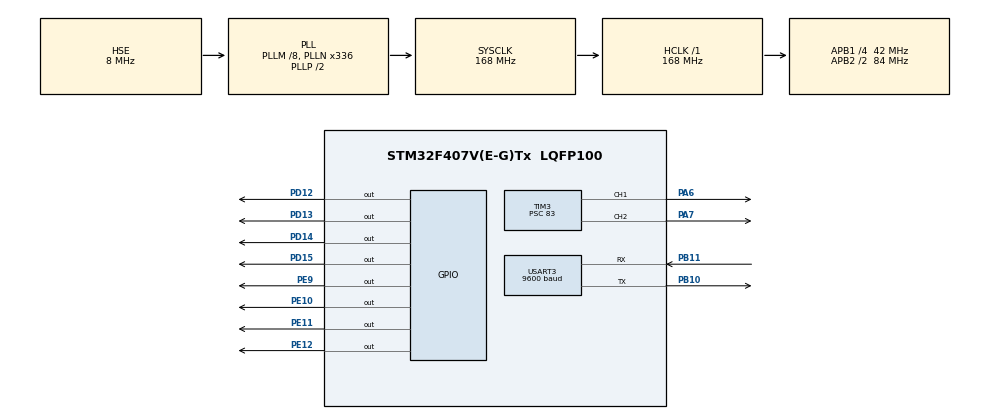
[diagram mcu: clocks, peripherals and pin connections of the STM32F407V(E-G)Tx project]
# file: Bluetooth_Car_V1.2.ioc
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Mcu.Family=STM32F4
Mcu.Name=STM32F407V(E-G)Tx
Mcu.Package=LQFP100
NVIC.PriorityGroup=NVIC_PRIORITYGROUP_0
NVIC.USART3_IRQn=true\:0\:0\:false\:false\:true\:true\:true
PA6.Signal=S_TIM3_CH1
PA7.Signal=S_TIM3_CH2
PB10.Mode=Asynchronous
PB10.Signal=USART3_TX
PB11.Mode=Asynchronous
PB11.Signal=USART3_RX
PD12.Signal=GPIO_Output
PD13.Signal=GPIO_Output
PD14.Signal=GPIO_Output
PD15.Signal=GPIO_Output
PE10.Signal=GPIO_Output
PE11.Signal=GPIO_Output
PE12.Signal=GPIO_Output
PE9.Signal=GPIO_Output
PH0-OSC_IN.Mode=HSE-External-Oscillator
PH0-OSC_IN.Signal=RCC_OSC_IN
PH1-OSC_OUT.Mode=HSE-External-Oscillator
PH1-OSC_OUT.Signal=RCC_OSC_OUT
ProjectManager.HeapSize=0x200
ProjectManager.StackSize=0x400
ProjectManager.TargetToolchain=STM32CubeIDE
RCC.48MHZClocksFreq_Value=48000000
RCC.AHBFreq_Value=168000000
RCC.APB1CLKDivider=RCC_HCLK_DIV4
RCC.APB1Freq_Value=42000000
RCC.APB1TimFreq_Value=84000000
RCC.APB2CLKDivider=RCC_HCLK_DIV2
RCC.APB2Freq_Value=84000000
RCC.APB2TimFreq_Value=168000000
RCC.CortexFreq_Value=168000000
RCC.HCLKFreq_Value=168000000
RCC.HSE_VALUE=8000000
RCC.HSI_VALUE=16000000
RCC.LSE_VALUE=32768
RCC.PLLM=8
RCC.PLLN=336
RCC.PLLQ=7
RCC.PLLSourceVirtual=RCC_PLLSOURCE_HSE
RCC.SYSCLKFreq_VALUE=168000000
RCC.SYSCLKSource=RCC_SYSCLKSOURCE_PLLCLK
RCC.VCOOutputFreq_Value=336000000
SH.S_TIM3_CH1.0=TIM3_CH1,PWM Generation1 CH1
SH.S_TIM3_CH2.0=TIM3_CH2,PWM Generation2 CH2
TIM3.Channel-PWM\ Generation1\ CH1=TIM_CHANNEL_1
TIM3.Channel-PWM\ Generation2\ CH2=TIM_CHANNEL_2
TIM3.Period=99
TIM3.Prescaler=83
USART3.BaudRate=9600
USART3.VirtualMode=VM_ASYNC
VP_TIM3_VS_ClockSourceINT.Mode=Internal
board=STM32F407G-DISC1

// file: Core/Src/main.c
/* USER CODE BEGIN Header */
/**
  ******************************************************************************
  * @file           : main.c
  * @brief          : Main program body
  ******************************************************************************
  * @attention
  *
  * <h2><center>&copy; Copyright (c) 2021 STMicroelectronics.
  * All rights reserved.</center></h2>
  *
  * This software component is licensed by ST under Ultimate Liberty license
  * SLA0044, the "License"; You may not use this file except in compliance with
  * the License. You may obtain a copy of the License at:
  *                             www.st.com/SLA0044
  *
  ******************************************************************************
  */
/* USER CODE END Header */
#include "main.h"

TIM_HandleTypeDef htim3;

UART_HandleTypeDef huart3;

void SystemClock_Config(void);
static void MX_GPIO_Init(void);
static void MX_USART3_UART_Init(void);
static void MX_TIM3_Init(void);

/* USER CODE BEGIN 0 */
extern char rx_buffer[50];
/* USER CODE END 0 */

int main(void)
{

  /* MCU Configuration--------------------------------------------------------*/

  /* Reset of all peripherals, Initializes the Flash interface and the Systick. */
  HAL_Init();

  /* Configure the system clock */
  SystemClock_Config();

  /* Initialize all configured peripherals */
  MX_GPIO_Init();
  MX_USART3_UART_Init();
  MX_TIM3_Init();
  /* USER CODE BEGIN 2 */

  HAL_UART_Receive_IT(&huart3, (uint8_t *)rx_buffer, 50);
  HAL_TIM_PWM_Start(&htim3, TIM_CHANNEL_1);
  HAL_TIM_PWM_Start(&htim3, TIM_CHANNEL_2);

  /* USER CODE END 2 */

  /* Infinite loop */
  while (1)
  {

  }
}

void SystemClock_Config(void)
{
  RCC_OscInitTypeDef RCC_OscInitStruct = {0};
  RCC_ClkInitTypeDef RCC_ClkInitStruct = {0};

  /** Configure the main internal regulator output voltage
  */
  __HAL_RCC_PWR_CLK_ENABLE();
  __HAL_PWR_VOLTAGESCALING_CONFIG(PWR_REGULATOR_VOLTAGE_SCALE1);
  /** Initializes the RCC Oscillators according to the specified parameters
  * in the RCC_OscInitTypeDef structure.
  */
  RCC_OscInitStruct.OscillatorType = RCC_OSCILLATORTYPE_HSE;
  RCC_OscInitStruct.HSEState = RCC_HSE_ON;
  RCC_OscInitStruct.PLL.PLLState = RCC_PLL_ON;
  RCC_OscInitStruct.PLL.PLLSource = RCC_PLLSOURCE_HSE;
  RCC_OscInitStruct.PLL.PLLM = 8;
  RCC_OscInitStruct.PLL.PLLN = 336;
  RCC_OscInitStruct.PLL.PLLP = RCC_PLLP_DIV2;
  RCC_OscInitStruct.PLL.PLLQ = 7;
  if (HAL_RCC_OscConfig(&RCC_OscInitStruct) != HAL_OK)
  {
    Error_Handler();
  }
  /** Initializes the CPU, AHB and APB buses clocks
  */
  RCC_ClkInitStruct.ClockType = RCC_CLOCKTYPE_HCLK|RCC_CLOCKTYPE_SYSCLK
                              |RCC_CLOCKTYPE_PCLK1|RCC_CLOCKTYPE_PCLK2;
  RCC_ClkInitStruct.SYSCLKSource = RCC_SYSCLKSOURCE_PLLCLK;
  RCC_ClkInitStruct.AHBCLKDivider = RCC_SYSCLK_DIV1;
  RCC_ClkInitStruct.APB1CLKDivider = RCC_HCLK_DIV4;
  RCC_ClkInitStruct.APB2CLKDivider = RCC_HCLK_DIV2;

  if (HAL_RCC_ClockConfig(&RCC_ClkInitStruct, FLASH_LATENCY_5) != HAL_OK)
  {
    Error_Handler();
  }
}

static void MX_TIM3_Init(void)
{

  TIM_ClockConfigTypeDef sClockSourceConfig = {0};
  TIM_MasterConfigTypeDef sMasterConfig = {0};
  TIM_OC_InitTypeDef sConfigOC = {0};

  htim3.Instance = TIM3;
  htim3.Init.Prescaler = 83;
  htim3.Init.CounterMode = TIM_COUNTERMODE_UP;
  htim3.Init.Period = 99;
  htim3.Init.ClockDivision = TIM_CLOCKDIVISION_DIV1;
  htim3.Init.AutoReloadPreload = TIM_AUTORELOAD_PRELOAD_DISABLE;
  if (HAL_TIM_Base_Init(&htim3) != HAL_OK)
  {
    Error_Handler();
  }
  sClockSourceConfig.ClockSource = TIM_CLOCKSOURCE_INTERNAL;
  if (HAL_TIM_ConfigClockSource(&htim3, &sClockSourceConfig) != HAL_OK)
  {
    Error_Handler();
  }
  if (HAL_TIM_PWM_Init(&htim3) != HAL_OK)
  {
    Error_Handler();
  }
  sMasterConfig.MasterOutputTrigger = TIM_TRGO_RESET;
  sMasterConfig.MasterSlaveMode = TIM_MASTERSLAVEMODE_DISABLE;
  if (HAL_TIMEx_MasterConfigSynchronization(&htim3, &sMasterConfig) != HAL_OK)
  {
    Error_Handler();
  }
  sConfigOC.OCMode = TIM_OCMODE_PWM1;
  sConfigOC.Pulse = 0;
  sConfigOC.OCPolarity = TIM_OCPOLARITY_HIGH;
  sConfigOC.OCFastMode = TIM_OCFAST_DISABLE;
  if (HAL_TIM_PWM_ConfigChannel(&htim3, &sConfigOC, TIM_CHANNEL_1) != HAL_OK)
  {
    Error_Handler();
  }
  if (HAL_TIM_PWM_ConfigChannel(&htim3, &sConfigOC, TIM_CHANNEL_2) != HAL_OK)
  {
    Error_Handler();
  }
  HAL_TIM_MspPostInit(&htim3);

}

static void MX_USART3_UART_Init(void)
{

  huart3.Instance = USART3;
  huart3.Init.BaudRate = 9600;
  huart3.Init.WordLength = UART_WORDLENGTH_8B;
  huart3.Init.StopBits = UART_STOPBITS_1;
  huart3.Init.Parity = UART_PARITY_NONE;
  huart3.Init.Mode = UART_MODE_TX_RX;
  huart3.Init.HwFlowCtl = UART_HWCONTROL_NONE;
  huart3.Init.OverSampling = UART_OVERSAMPLING_16;
  if (HAL_UART_Init(&huart3) != HAL_OK)
  {
    Error_Handler();
  }

}

static void MX_GPIO_Init(void)
{
  GPIO_InitTypeDef GPIO_InitStruct = {0};

  /* GPIO Ports Clock Enable */
  __HAL_RCC_GPIOH_CLK_ENABLE();
  __HAL_RCC_GPIOA_CLK_ENABLE();
  __HAL_RCC_GPIOE_CLK_ENABLE();
  __HAL_RCC_GPIOB_CLK_ENABLE();
  __HAL_RCC_GPIOD_CLK_ENABLE();

  /*Configure GPIO pin Output Level */
  HAL_GPIO_WritePin(GPIOE, GPIO_PIN_9|GPIO_PIN_10|GPIO_PIN_11|GPIO_PIN_12, GPIO_PIN_RESET);

  /*Configure GPIO pin Output Level */
  HAL_GPIO_WritePin(GPIOD, GPIO_PIN_12|GPIO_PIN_13|GPIO_PIN_14|GPIO_PIN_15, GPIO_PIN_RESET);

  /*Configure GPIO pins : PE9 PE10 PE11 PE12 */
  GPIO_InitStruct.Pin = GPIO_PIN_9|GPIO_PIN_10|GPIO_PIN_11|GPIO_PIN_12;
  GPIO_InitStruct.Mode = GPIO_MODE_OUTPUT_PP;
  GPIO_InitStruct.Pull = GPIO_NOPULL;
  GPIO_InitStruct.Speed = GPIO_SPEED_FREQ_LOW;
  HAL_GPIO_Init(GPIOE, &GPIO_InitStruct);

  /*Configure GPIO pins : PD12 PD13 PD14 PD15 */
  GPIO_InitStruct.Pin = GPIO_PIN_12|GPIO_PIN_13|GPIO_PIN_14|GPIO_PIN_15;
  GPIO_InitStruct.Mode = GPIO_MODE_OUTPUT_PP;
  GPIO_InitStruct.Pull = GPIO_NOPULL;
  GPIO_InitStruct.Speed = GPIO_SPEED_FREQ_LOW;
  HAL_GPIO_Init(GPIOD, &GPIO_InitStruct);

}

void Error_Handler(void)
{
  __disable_irq();
  while (1)
  {
  }
}

/************************ (C) COPYRIGHT STMicroelectronics *****END OF FILE****/
